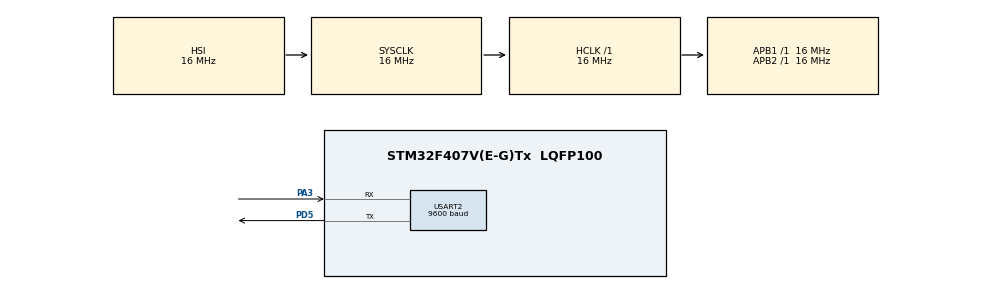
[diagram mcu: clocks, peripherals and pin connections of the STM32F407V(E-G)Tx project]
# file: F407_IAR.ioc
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Mcu.Family=STM32F4
Mcu.Name=STM32F407V(E-G)Tx
Mcu.Package=LQFP100
NVIC.PriorityGroup=NVIC_PRIORITYGROUP_4
NVIC.USART2_IRQn=true\:0\:0\:false\:false\:true\:true\:true\:true
PA13.Mode=Serial_Wire
PA13.Signal=SYS_JTMS-SWDIO
PA14.Mode=Serial_Wire
PA14.Signal=SYS_JTCK-SWCLK
PA3.Mode=Asynchronous
PA3.Signal=USART2_RX
PD5.Mode=Asynchronous
PD5.Signal=USART2_TX
PH0-OSC_IN.Mode=HSE-External-Oscillator
PH0-OSC_IN.Signal=RCC_OSC_IN
PH1-OSC_OUT.Mode=HSE-External-Oscillator
PH1-OSC_OUT.Signal=RCC_OSC_OUT
ProjectManager.HeapSize=0x200
ProjectManager.StackSize=0x400
ProjectManager.TargetToolchain=MDK-ARM V5.32
RCC.AHBFreq_Value=16000000
RCC.APB1Freq_Value=16000000
RCC.APB2Freq_Value=16000000
RCC.CortexFreq_Value=16000000
RCC.HSE_VALUE=25000000
RCC.HSI_VALUE=16000000
RCC.LSE_VALUE=32768
RCC.SYSCLKFreq_VALUE=16000000
RCC.VCOOutputFreq_Value=192000000
USART2.BaudRate=9600
USART2.VirtualMode=VM_ASYNC
board=custom

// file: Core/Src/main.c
/* USER CODE BEGIN Header */
/**
  ******************************************************************************
  * @file           : main.c
  * @brief          : Main program body
  ******************************************************************************
  * @attention
  *
  * Copyright (c) 2026 STMicroelectronics.
  * All rights reserved.
  *
  * This software is licensed under terms that can be found in the LICENSE file
  * in the root directory of this software component.
  * If no LICENSE file comes with this software, it is provided AS-IS.
  *
  ******************************************************************************
  */
/* USER CODE END Header */
#include "main.h"
#include "usart.h"
#include "gpio.h"

/* USER CODE BEGIN Includes */
#include "boot_config.h"
#include "SEGGER_RTT.h"
#include "ring_buffer.h"
#include "ota_protocol.h"
#include "flash_ops.h"
#include "metadata.h"
#include "ota_manager.h"
#include "crc32.h"
/* USER CODE END Includes */

/* USER CODE BEGIN PD */
extern void boot_jump_to_app(uint32_t app_addr);
extern RingBuffer_t bt_rx_ring;
/* USER CODE END PD */

void SystemClock_Config(void);

int main(void)
{

  /* MCU Configuration--------------------------------------------------------*/

  /* Reset of all peripherals, Initializes the Flash interface and the Systick. */
  HAL_Init();

  /* Configure the system clock */
  SystemClock_Config();

  /* Initialize all configured peripherals */
  MX_GPIO_Init();
  MX_USART2_UART_Init();

  /* Infinite loop */
  /* USER CODE BEGIN WHILE */
  HAL_SYSTICK_Config(HAL_RCC_GetHCLKFreq()/1000);

  SEGGER_RTT_printf(0,"version:%d.%d\r\n",(BOOTLOADER_VERSION>>8)&0xFF,BOOTLOADER_VERSION&0xFF);
  SEGGER_RTT_printf(0,"flash:%dKB\r\n", BOOTLOADER_SIZE/1024);
  SEGGER_RTT_printf(0,"APP_ADDR:0x%08X\r\n", APP_BASE);

  // 判断 App 是否有效（看 Metadata 的 magic），有效则跳转
  if(Metadata_IsValid())
  {
    uint32_t app_pc = *(volatile uint32_t *)(APP_BASE + 4);
    SEGGER_RTT_printf(0,"APP_PC:0x%08X\r\n",app_pc);
    SEGGER_RTT_printf(0,"[DIAG] Vector: ");
    for(int i = 0; i < 8; i++)
    {
      SEGGER_RTT_printf(0,"%02X ",*(volatile uint8_t *)(APP_BASE + i));
    }
    SEGGER_RTT_printf(0,"\r\n");

    SEGGER_RTT_printf(0,"APP valid, jump to app\r\n");
    HAL_Delay(1000);
    __disable_irq();
    boot_jump_to_app(APP_BASE);
    Error_Handler();
  }
  else
  {
    FrameParser_t parser;
    FrameParser_Init(&parser);
    CRC32_Init();

    while(1)
    {
      uint8_t byte;

      while (RingBuffer_Get(&bt_rx_ring,&byte))
      {
        OtaFrame_t frame;
        int ret = FrameParser_Feed(&parser,byte,&frame);

        if(ret == 1)
        {
          SEGGER_RTT_printf(0, "[FRAME] CMD:0x%02X LEN:%d\r\n",frame.cmd, frame.data_len);
          OTA_HandleFrame(&frame);
        }
        else if(ret == -1)
        {
          SEGGER_RTT_printf(0, "ERR] frame error\r\n");
        }
      }
    }
  }
  /* USER CODE END WHILE */

}

void SystemClock_Config(void)
{
  RCC_OscInitTypeDef RCC_OscInitStruct = {0};
  RCC_ClkInitTypeDef RCC_ClkInitStruct = {0};

  /** Configure the main internal regulator output voltage
  */
  __HAL_RCC_PWR_CLK_ENABLE();
  __HAL_PWR_VOLTAGESCALING_CONFIG(PWR_REGULATOR_VOLTAGE_SCALE1);

  /** Initializes the RCC Oscillators according to the specified parameters
  * in the RCC_OscInitTypeDef structure.
  */
  RCC_OscInitStruct.OscillatorType = RCC_OSCILLATORTYPE_HSI;
  RCC_OscInitStruct.HSIState = RCC_HSI_ON;
  RCC_OscInitStruct.HSICalibrationValue = RCC_HSICALIBRATION_DEFAULT;
  RCC_OscInitStruct.PLL.PLLState = RCC_PLL_NONE;
  if (HAL_RCC_OscConfig(&RCC_OscInitStruct) != HAL_OK)
  {
    Error_Handler();
  }

  /** Initializes the CPU, AHB and APB buses clocks
  */
  RCC_ClkInitStruct.ClockType = RCC_CLOCKTYPE_HCLK|RCC_CLOCKTYPE_SYSCLK
                              |RCC_CLOCKTYPE_PCLK1|RCC_CLOCKTYPE_PCLK2;
  RCC_ClkInitStruct.SYSCLKSource = RCC_SYSCLKSOURCE_HSI;
  RCC_ClkInitStruct.AHBCLKDivider = RCC_SYSCLK_DIV1;
  RCC_ClkInitStruct.APB1CLKDivider = RCC_HCLK_DIV1;
  RCC_ClkInitStruct.APB2CLKDivider = RCC_HCLK_DIV1;

  if (HAL_RCC_ClockConfig(&RCC_ClkInitStruct, FLASH_LATENCY_0) != HAL_OK)
  {
    Error_Handler();
  }
}

void Error_Handler(void)
{
  __disable_irq();
  while (1)
  {
  }
}
